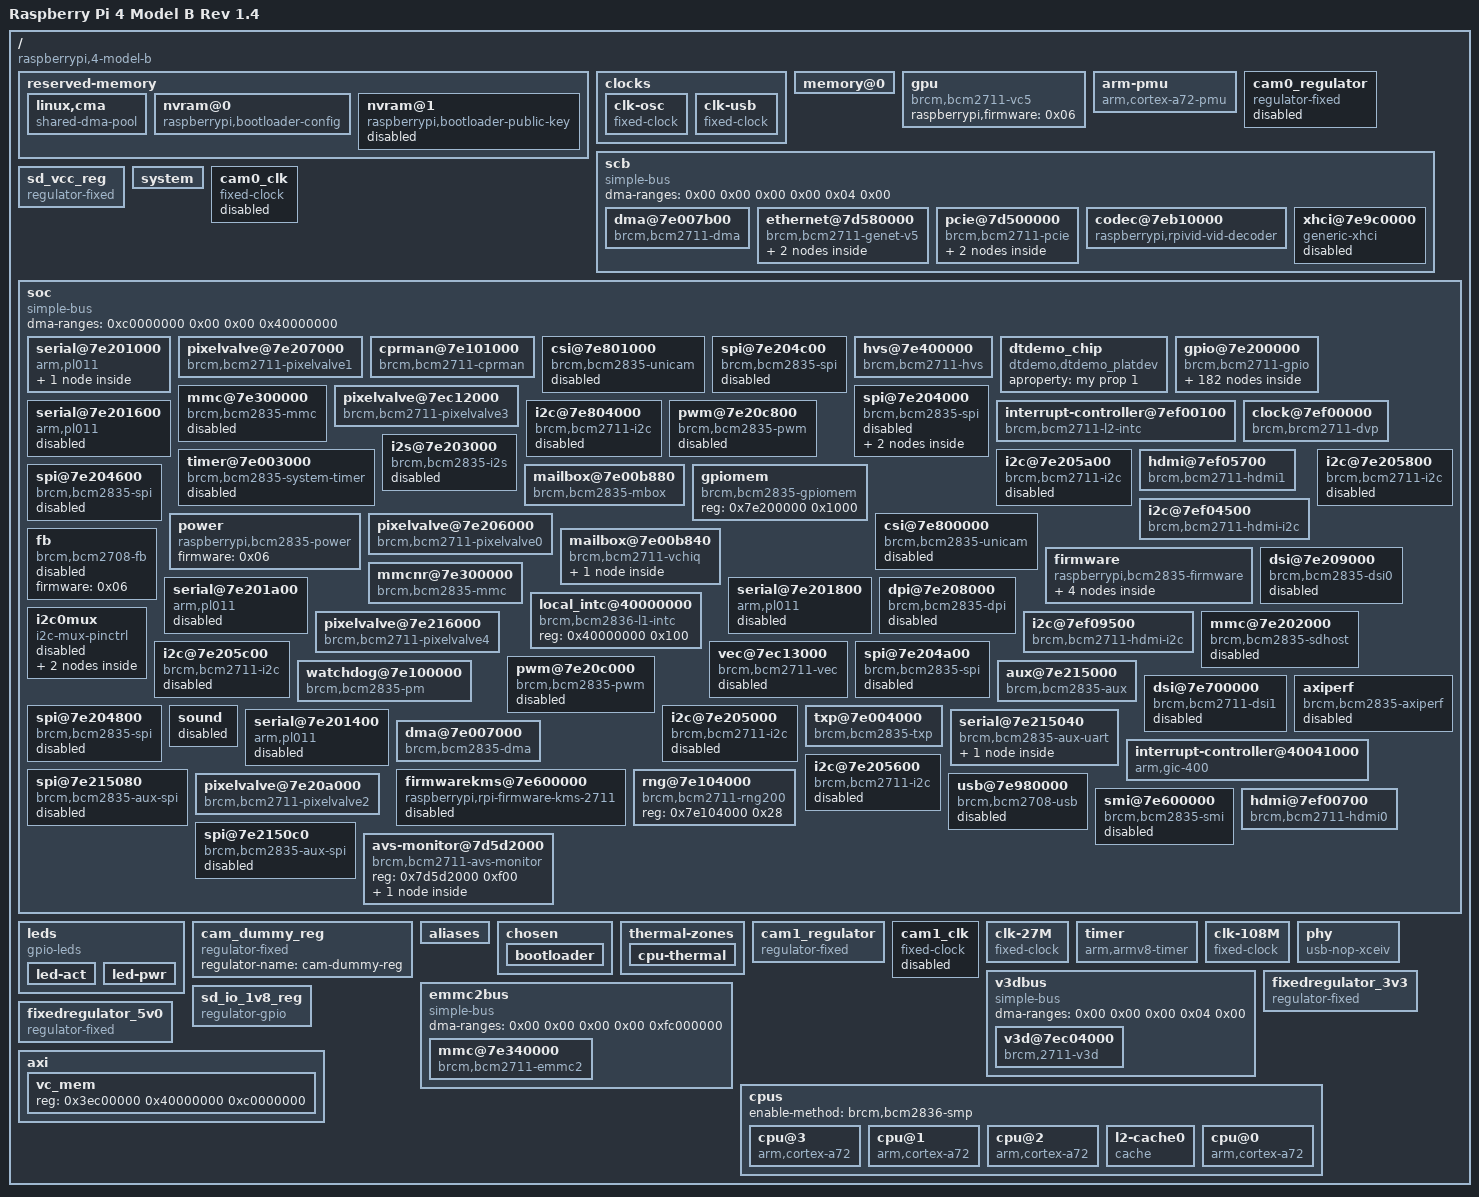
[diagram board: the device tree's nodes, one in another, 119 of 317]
/dts-v1/;

/ {
	compatible = "raspberrypi,4-model-b\0brcm,bcm2711";
	serial-number = "10000000e03e8661";
	model = "Raspberry Pi 4 Model B Rev 1.4";
	memreserve = <0x3b400000 0x4c00000>;
	interrupt-parent = <0x01>;
	#address-cells = <0x02>;
	#size-cells = <0x01>;

	reserved-memory {
		ranges;
		#address-cells = <0x02>;
		#size-cells = <0x01>;
		phandle = <0x44>;

		linux,cma {
			reusable;
			compatible = "shared-dma-pool";
			alloc-ranges = <0x00 0x00 0x30000000>;
			size = <0x14000000>;
			phandle = <0x45>;
			linux,cma-default;
		};

		nvram@0 {
			compatible = "raspberrypi,bootloader-config\0nvmem-rmem";
			status = "okay";
			#address-cells = <0x01>;
			#size-cells = <0x01>;
			no-map;
			phandle = <0x46>;
			reg = <0x00 0x3ef629c0 0x36>;
		};

		nvram@1 {
			compatible = "raspberrypi,bootloader-public-key\0nvmem-rmem";
			status = "disabled";
			#address-cells = <0x01>;
			#size-cells = <0x01>;
			no-map;
			phandle = <0x47>;
			reg = <0x00 0x00 0x00>;
		};
	};

	clocks {

		clk-osc {
			compatible = "fixed-clock";
			#clock-cells = <0x00>;
			phandle = <0x03>;
			clock-output-names = "osc";
			clock-frequency = <0x337f980>;
		};

		clk-usb {
			compatible = "fixed-clock";
			#clock-cells = <0x00>;
			phandle = <0x19>;
			clock-output-names = "otg";
			clock-frequency = <0x1c9c3800>;
		};
	};

	memory@0 {
		device_type = "memory";
		reg = <0x00 0x00 0x3b400000 0x00 0x40000000 0x40000000>;
	};

	__overrides__ {
		pwr_led_gpio = "\0\0\0Bgpios:4";
		cam0-led-ctrl;
		eth_led1 = "\0\0\0/led-modes:4";
		i2c1 = "\0\0\06status";
		i2c_vc = [00 00 00 10 73 74 61 74 75 73 00 00 00 00 35 73 74 61 74 75 73 00];
		sd_overclock = "\0\0\0:brcm,overclock-50:0";
		sdio_overclock = "\0\0\0;brcm,overclock-50:0\0\0\0\0<brcm,overclock-50:0";
		i2c0_baudrate = [00 00 00 10 63 6c 6f 63 6b 2d 66 72 65 71 75 65 6e 63 79 3a 30 00];
		sd_pio_limit = "\0\0\0:brcm,pio-limit:0";
		act_led_trigger = "\0\0\0Alinux,default-trigger";
		audio = "\0\0\07status";
		sd_debug = "\0\0\0:brcm,debug";
		cam0-pwdn-ctrl;
		cache_line_size;
		cam0-led;
		i2c1_baudrate = "\0\0\06clock-frequency:0";
		spi = "\0\0\04status";
		i2c_arm = "\0\0\06status";
		sd = "\0\0\0@status";
		pcie = "\0\0\0-status";
		pwr_led_activelow = "\0\0\0Bgpios:8";
		uart0 = "\0\0\01status";
		i2s = "\0\0\03status";
		eth_led0 = "\0\0\0/led-modes:0";
		i2c0 = [00 00 00 10 73 74 61 74 75 73 00 00 00 00 35 73 74 61 74 75 73 00];
		arm_freq;
		spi_dma4 = <0x34 0x646d6173 0x3a303d00 0x43 0x34 0x646d6173 0x3a383d00 0x43>;
		watchdog = "\0\0\08status";
		krnbt = "\0\0\00status";
		i2c_baudrate = "\0\0\06clock-frequency:0";
		i2c_vc_baudrate = [00 00 00 10 63 6c 6f 63 6b 2d 66 72 65 71 75 65 6e 63 79 3a 30 00];
		sd_poll_once = "\0\0\0@non-removable?";
		axiperf = "\0\0\0=status";
		act_led_activelow = "\0\0\0Agpios:8";
		krnbt_baudrate = "\0\0\00max-speed:0";
		sd_force_pio = "\0\0\0:brcm,force-pio?";
		pwr_led_trigger = "\0\0\0Blinux,default-trigger";
		hdmi = "\0\0\0>status\0\0\0\0?status";
		cam0-pwdn;
		uart1 = "\0\0\02status";
		i2c_arm_baudrate = "\0\0\06clock-frequency:0";
		random = "\0\0\09status";
		act_led_gpio = "\0\0\0Agpios:4";
		i2c = "\0\0\06status";
	};

	gpu {
		compatible = "brcm,bcm2711-vc5";
		status = "okay";
		phandle = <0xdb>;
		raspberrypi,firmware = <0x06>;
	};

	arm-pmu {
		compatible = "arm,cortex-a72-pmu\0arm,armv8-pmuv3\0arm,cortex-a7-pmu";
		interrupts = <0x00 0x10 0x04 0x00 0x11 0x04 0x00 0x12 0x04 0x00 0x13 0x04>;
		interrupt-affinity = <0x28 0x29 0x2a 0x2b>;
	};

	cam0_regulator {
		compatible = "regulator-fixed";
		enable-active-high;
		status = "disabled";
		phandle = <0xe5>;
		regulator-name = "cam0-reg";
	};

	scb {
		compatible = "simple-bus";
		ranges = <0x00 0x7c000000 0x00 0xfc000000 0x00 0x3800000 0x00 0x40000000 0x00 0xff800000 0x00 0x800000 0x06 0x00 0x06 0x00 0x00 0x40000000 0x00 0x00 0x00 0x00 0x00 0xfc000000>;
		#address-cells = <0x02>;
		#size-cells = <0x02>;
		phandle = <0xde>;
		dma-ranges = <0x00 0x00 0x00 0x00 0x04 0x00>;

		dma@7e007b00 {
			#dma-cells = <0x01>;
			compatible = "brcm,bcm2711-dma";
			brcm,dma-channel-mask = <0x3000>;
			interrupts = <0x00 0x59 0x04 0x00 0x5a 0x04 0x00 0x5b 0x04 0x00 0x5c 0x04>;
			phandle = <0x43>;
			reg = <0x00 0x7e007b00 0x00 0x400>;
			interrupt-names = "dma11\0dma12\0dma13\0dma14";
		};

		ethernet@7d580000 {
			phy-handle = <0x2f>;
			compatible = "brcm,bcm2711-genet-v5";
			local-mac-address = [e4 5f 01 49 32 b5];
			status = "okay";
			#address-cells = <0x01>;
			interrupts = <0x00 0x9d 0x04 0x00 0x9e 0x04>;
			#size-cells = <0x01>;
			phandle = <0xdf>;
			reg = <0x00 0x7d580000 0x00 0x10000>;
			phy-mode = "rgmii-rxid";

			mdio@e14 {
				compatible = "brcm,genet-mdio-v5";
				reg-names = "mdio";
				#address-cells = <0x01>;
				#size-cells = <0x00>;
				phandle = <0xe0>;
				reg = <0xe14 0x08>;

				ethernet-phy@1 {
					phandle = <0x2f>;
					reg = <0x01>;
					led-modes = <0x00 0x08>;
				};
			};
		};

		pcie@7d500000 {
			compatible = "brcm,bcm2711-pcie\0brcm,bcm7445-pcie";
			device_type = "pci";
			interrupt-map-mask = <0x00 0x00 0x00 0x07>;
			ranges = <0x2000000 0x00 0xc0000000 0x06 0x00 0x00 0x40000000>;
			#interrupt-cells = <0x01>;
			#address-cells = <0x03>;
			interrupts = <0x00 0x93 0x04 0x00 0x94 0x04>;
			interrupt-map = <0x00 0x00 0x00 0x01 0x01 0x00 0x8f 0x04 0x00 0x00 0x00 0x02 0x01 0x00 0x90 0x04 0x00 0x00 0x00 0x03 0x01 0x00 0x91 0x04 0x00 0x00 0x00 0x04 0x01 0x00 0x92 0x04>;
			#size-cells = <0x02>;
			phandle = <0x2d>;
			msi-parent = <0x2d>;
			reg = <0x00 0x7d500000 0x00 0x9310>;
			dma-ranges = <0x2000000 0x04 0x00 0x00 0x00 0x00 0x80000000>;
			brcm,enable-ssc;
			interrupt-names = "pcie\0msi";
			msi-controller;

			pci@0,0 {
				device_type = "pci";
				ranges;
				#address-cells = <0x03>;
				#size-cells = <0x02>;
				reg = <0x00 0x00 0x00 0x00 0x00>;

				usb@0,0 {
					resets = <0x2e 0x00>;
					reg = <0x00 0x00 0x00 0x00 0x00>;
				};
			};
		};

		codec@7eb10000 {
			compatible = "raspberrypi,rpivid-vid-decoder";
			clocks = <0x17 0x0b>;
			reg-names = "intc\0hevc";
			clock-names = "hevc";
			interrupts = <0x00 0x62 0x04>;
			reg = <0x00 0x7eb10000 0x00 0x1000 0x00 0x7eb00000 0x00 0x10000>;
		};

		xhci@7e9c0000 {
			power-domains = <0x13 0x06>;
			compatible = "generic-xhci";
			status = "disabled";
			interrupts = <0x00 0xb0 0x04>;
			phandle = <0xe1>;
			reg = <0x00 0x7e9c0000 0x00 0x100000>;
		};
	};

	sd_vcc_reg {
		compatible = "regulator-fixed";
		regulator-boot-on;
		enable-active-high;
		gpio = <0x0b 0x06 0x00>;
		phandle = <0x27>;
		regulator-min-microvolt = <0x325aa0>;
		regulator-max-microvolt = <0x325aa0>;
		regulator-name = "vcc-sd";
	};

	system {
		linux,serial = <0x10000000 0xe03e8661>;
		linux,revision = <0xb03114>;
	};

	__symbols__ {
		uart0_gpio14 = "/soc/gpio@7e200000/uart0_gpio14";
		ddc1 = "/soc/i2c@7ef09500";
		pwm = "/soc/pwm@7e20c000";
		i2c3 = "/soc/i2c@7e205600";
		gpclk1_gpio5 = "/soc/gpio@7e200000/gpclk1_gpio5";
		clk_usb = "/clocks/clk-usb";
		pixelvalve0 = "/soc/pixelvalve@7e206000";
		mii_gpio36 = "/soc/gpio@7e200000/mii_gpio36";
		minibt = "/soc/serial@7e215040/bluetooth";
		uart0_ctsrts_gpio30 = "/soc/gpio@7e200000/uart0_ctsrts_gpio30";
		spi3_pins = "/soc/gpio@7e200000/spi3_pins";
		uart4_ctsrts_gpio10 = "/soc/gpio@7e200000/uart4_ctsrts_gpio10";
		uart1_ctsrts_gpio16 = "/soc/gpio@7e200000/uart1_ctsrts_gpio16";
		uart0_gpio32 = "/soc/gpio@7e200000/uart0_gpio32";
		rgmii_irq_gpio39 = "/soc/gpio@7e200000/rgmii_irq_gpio39";
		i2c4_pins = "/soc/gpio@7e200000/i2c4";
		spi2 = "/soc/spi@7e2150c0";
		i2c0if = "/soc/i2c@7e205000";
		dsi1 = "/soc/dsi@7e700000";
		uart5_ctsrts_gpio14 = "/soc/gpio@7e200000/uart5_ctsrts_gpio14";
		clocks = "/soc/cprman@7e101000";
		i2c1 = "/soc/i2c@7e804000";
		i2c_vc = "/soc/i2c0mux/i2c@0";
		alt0 = "/soc/gpio@7e200000/alt0";
		uart4_pins = "/soc/gpio@7e200000/uart4_pins";
		rgmii_gpio35 = "/soc/gpio@7e200000/rgmii_gpio35";
		firmwarekms = "/soc/firmwarekms@7e600000";
		smi = "/soc/smi@7e600000";
		i2c5_gpio12 = "/soc/gpio@7e200000/i2c5_gpio12";
		uart1_ctsrts_gpio42 = "/soc/gpio@7e200000/uart1_ctsrts_gpio42";
		hdmi1 = "/soc/hdmi@7ef05700";
		spi0 = "/soc/spi@7e204000";
		bt = "/soc/serial@7e201000/bluetooth";
		thermal = "/soc/avs-monitor@7d5d2000/thermal";
		vdd_5v0_reg = "/fixedregulator_5v0";
		pwm1_1_gpio41 = "/soc/gpio@7e200000/pwm1_1_gpio41";
		vchiq = "/soc/mailbox@7e00b840";
		sdhost = "/soc/mmc@7e202000";
		aux = "/soc/aux@7e215000";
		cam0_regulator = "/cam0_regulator";
		gpio = "/soc/gpio@7e200000";
		gpclk0_gpio4 = "/soc/gpio@7e200000/gpclk0_gpio4";
		blconfig = "/reserved-memory/nvram@0";
		i2c3_pins = "/soc/gpio@7e200000/i2c3";
		rgmii_mdio_gpio37 = "/soc/gpio@7e200000/rgmii_mdio_gpio37";
		sdhci = "/soc/mmc@7e300000";
		blpubkey = "/reserved-memory/nvram@1";
		i2c5_gpio10 = "/soc/gpio@7e200000/i2c5_gpio10";
		gpclk2_gpio43 = "/soc/gpio@7e200000/gpclk2_gpio43";
		spi5_gpio12 = "/soc/gpio@7e200000/spi5_gpio12";
		cam1_reg = "/cam1_regulator";
		i2c3_gpio4 = "/soc/gpio@7e200000/i2c3_gpio4";
		scb = "/scb";
		xhci = "/scb/xhci@7e9c0000";
		dpi = "/soc/dpi@7e208000";
		dpi_18bit_cpadhi_gpio2 = "/soc/gpio@7e200000/dpi_18bit_cpadhi_gpio2";
		v3d = "/v3dbus/v3d@7ec04000";
		gpclk0_gpio49 = "/soc/gpio@7e200000/gpclk0_gpio49";
		audio = "/soc/mailbox@7e00b840/bcm2835_audio";
		genet = "/scb/ethernet@7d580000";
		vdd_3v3_reg = "/fixedregulator_3v3";
		uart3_pins = "/soc/gpio@7e200000/uart3_pins";
		phy1 = "/scb/ethernet@7d580000/mdio@e14/ethernet-phy@1";
		spi5_cs_pins = "/soc/gpio@7e200000/spi5_cs_pins";
		uart1_ctsrts_gpio30 = "/soc/gpio@7e200000/uart1_ctsrts_gpio30";
		gpioout = "/soc/gpio@7e200000/gpioout";
		sd_vcc_reg = "/sd_vcc_reg";
		dma = "/soc/dma@7e007000";
		spidev1 = "/soc/spi@7e204000/spidev@1";
		mmcnr = "/soc/mmcnr@7e300000";
		pwm0_0_gpio18 = "/soc/gpio@7e200000/pwm0_0_gpio18";
		gpclk2_gpio51 = "/soc/gpio@7e200000/gpclk2_gpio51";
		spi0_gpio35 = "/soc/gpio@7e200000/spi0_gpio35";
		uart4 = "/soc/serial@7e201800";
		vc4 = "/gpu";
		firmware_clocks = "/soc/firmware/clocks";
		uart5_gpio12 = "/soc/gpio@7e200000/uart5_gpio12";
		i2c3_gpio2 = "/soc/gpio@7e200000/i2c3_gpio2";
		cpu3 = "/cpus/cpu@3";
		dpi_18bit_cpadhi_gpio0 = "/soc/gpio@7e200000/dpi_18bit_cpadhi_gpio0";
		jtag_gpio48 = "/soc/gpio@7e200000/jtag_gpio48";
		cam0_clk = "/cam0_clk";
		pcm_gpio28 = "/soc/gpio@7e200000/pcm_gpio28";
		dpi_gpio0 = "/soc/gpio@7e200000/dpi_gpio0";
		power = "/soc/power";
		soc = "/soc";
		i2c6 = "/soc/i2c@7e205c00";
		pixelvalve3 = "/soc/pixelvalve@7ec12000";
		i2c0_gpio0 = "/soc/gpio@7e200000/i2c0_gpio0";
		pcm_gpio18 = "/soc/gpio@7e200000/pcm_gpio18";
		aon_intr = "/soc/interrupt-controller@7ef00100";
		i2c4_gpio8 = "/soc/gpio@7e200000/i2c4_gpio8";
		reset = "/soc/firmware/reset";
		dma40 = "/scb/dma@7e007b00";
		leds = "/leds";
		pwm1 = "/soc/pwm@7e20c800";
		system_timer = "/soc/timer@7e003000";
		uart2 = "/soc/serial@7e201400";
		uart2_pins = "/soc/gpio@7e200000/uart2_pins";
		csi1 = "/soc/csi@7e801000";
		spi2_gpio46 = "/soc/gpio@7e200000/spi2_gpio46";
		i2s_pins = "/soc/gpio@7e200000/i2s";
		cam_dummy_reg = "/cam_dummy_reg";
		firmware = "/soc/firmware";
		spi5 = "/soc/spi@7e204a00";
		cpu1 = "/cpus/cpu@1";
		spi3_gpio0 = "/soc/gpio@7e200000/spi3_gpio0";
		mmc = "/soc/mmc@7e300000";
		l2 = "/cpus/l2-cache0";
		dpi_18bit_gpio2 = "/soc/gpio@7e200000/dpi_18bit_gpio2";
		pcie0 = "/scb/pcie@7d500000";
		usbphy = "/phy";
		pwm0_0_gpio52 = "/soc/gpio@7e200000/pwm0_0_gpio52";
		i2c4 = "/soc/i2c@7e205800";
		pixelvalve1 = "/soc/pixelvalve@7e207000";
		i2c6_gpio0 = "/soc/gpio@7e200000/i2c6_gpio0";
		i2c1_gpio46 = "/soc/gpio@7e200000/i2c1_gpio46";
		spi = "/soc/spi@7e204000";
		spi0_pins = "/soc/gpio@7e200000/spi0_pins";
		i2c_arm = "/soc/i2c@7e804000";
		i2c4_gpio6 = "/soc/gpio@7e200000/i2c4_gpio6";
		clk_osc = "/clocks/clk-osc";
		uart0 = "/soc/serial@7e201000";
		i2c1_pins = "/soc/gpio@7e200000/i2c1";
		rmem = "/reserved-memory";
		cpu_thermal = "/thermal-zones/cpu-thermal";
		spi3 = "/soc/spi@7e204600";
		fb = "/soc/fb";
		txp = "/soc/txp@7e004000";
		dpi_18bit_gpio0 = "/soc/gpio@7e200000/dpi_18bit_gpio0";
		spi0_gpio7 = "/soc/gpio@7e200000/spi0_gpio7";
		ddc0 = "/soc/i2c@7ef04500";
		uart1_pins = "/soc/gpio@7e200000/uart1_pins";
		spi6_cs_pins = "/soc/gpio@7e200000/spi6_cs_pins";
		pwm0_0_gpio12 = "/soc/gpio@7e200000/pwm0_0_gpio12";
		i2c1_gpio44 = "/soc/gpio@7e200000/i2c1_gpio44";
		cma = "/reserved-memory/linux,cma";
		pwm0_1_gpio19 = "/soc/gpio@7e200000/pwm0_1_gpio19";
		spi6_pins = "/soc/gpio@7e200000/spi6_pins";
		i2c0_gpio28 = "/soc/gpio@7e200000/i2c0_gpio28";
		spi4_gpio4 = "/soc/gpio@7e200000/spi4_gpio4";
		avs_monitor = "/soc/avs-monitor@7d5d2000";
		cam1_clk = "/cam1_clk";
		i2s = "/soc/i2s@7e203000";
		emmc_gpio48 = "/soc/gpio@7e200000/emmc_gpio48";
		spi1 = "/soc/spi@7e215080";
		usb = "/soc/usb@7e980000";
		dsi0 = "/soc/dsi@7e209000";
		i2c0_gpio46 = "/soc/gpio@7e200000/i2c0_gpio46";
		i2c1_gpio2 = "/soc/gpio@7e200000/i2c1_gpio2";
		uart2_gpio0 = "/soc/gpio@7e200000/uart2_gpio0";
		dvp = "/soc/clock@7ef00000";
		expgpio = "/soc/firmware/gpio";
		uart0_ctsrts_gpio38 = "/soc/gpio@7e200000/uart0_ctsrts_gpio38";
		pm = "/soc/watchdog@7e100000";
		audio_pins = "/soc/gpio@7e200000/audio_pins";
		i2c0 = "/soc/i2c0mux/i2c@0";
		pcm_gpio50 = "/soc/gpio@7e200000/pcm_gpio50";
		spi1_gpio16 = "/soc/gpio@7e200000/spi1_gpio16";
		i2c0mux = "/soc/i2c0mux";
		i2c_csi_dsi = "/soc/i2c0mux/i2c@1";
		i2c0_pins = "/soc/gpio@7e200000/i2c0";
		spi3_cs_pins = "/soc/gpio@7e200000/spi3_cs_pins";
		pwr_led = "/leds/led-pwr";
		watchdog = "/soc/watchdog@7e100000";
		jtag_gpio22 = "/soc/gpio@7e200000/jtag_gpio22";
		pwm0_1_gpio45 = "/soc/gpio@7e200000/pwm0_1_gpio45";
		clk_27MHz = "/clk-27M";
		rgmii_mdio_gpio28 = "/soc/gpio@7e200000/rgmii_mdio_gpio28";
		hdmi0 = "/soc/hdmi@7ef00700";
		spi2_gpio40 = "/soc/gpio@7e200000/spi2_gpio40";
		uart0_pins = "/soc/gpio@7e200000/uart0_pins";
		vec = "/soc/vec@7ec13000";
		local_intc = "/soc/local_intc@40000000";
		i2c0_gpio44 = "/soc/gpio@7e200000/i2c0_gpio44";
		spi0_gpio46 = "/soc/gpio@7e200000/spi0_gpio46";
		spi5_pins = "/soc/gpio@7e200000/spi5_pins";
		axiperf = "/soc/axiperf";
		gicv2 = "/soc/interrupt-controller@40041000";
		pwm0_1_gpio53 = "/soc/gpio@7e200000/pwm0_1_gpio53";
		spi0_cs_pins = "/soc/gpio@7e200000/spi0_cs_pins";
		i2c6_pins = "/soc/gpio@7e200000/i2c6";
		sound = "/soc/sound";
		uart5 = "/soc/serial@7e201a00";
		hvs = "/soc/hvs@7e400000";
		uart2_ctsrts_gpio2 = "/soc/gpio@7e200000/uart2_ctsrts_gpio2";
		spi6_gpio18 = "/soc/gpio@7e200000/spi6_gpio18";
		uart3_gpio4 = "/soc/gpio@7e200000/uart3_gpio4";
		rgmii_irq_gpio34 = "/soc/gpio@7e200000/rgmii_irq_gpio34";
		uart3_ctsrts_gpio6 = "/soc/gpio@7e200000/uart3_ctsrts_gpio6";
		uart0_ctsrts_gpio16 = "/soc/gpio@7e200000/uart0_ctsrts_gpio16";
		v3dbus = "/v3dbus";
		act_led = "/leds/led-act";
		gpclk2_gpio6 = "/soc/gpio@7e200000/gpclk2_gpio6";
		spidev0 = "/soc/spi@7e204000/spidev@0";
		pixelvalve4 = "/soc/pixelvalve@7e216000";
		sdhost_gpio48 = "/soc/gpio@7e200000/sdhost_gpio48";
		genet_mdio = "/scb/ethernet@7d580000/mdio@e14";
		bt_pins = "/soc/gpio@7e200000/bt_pins";
		dpi_16bit_gpio2 = "/soc/gpio@7e200000/dpi_16bit_gpio2";
		emmc_gpio34 = "/soc/gpio@7e200000/emmc_gpio34";
		gpclk1_gpio44 = "/soc/gpio@7e200000/gpclk1_gpio44";
		uart1_gpio14 = "/soc/gpio@7e200000/uart1_gpio14";
		uart0_gpio36 = "/soc/gpio@7e200000/uart0_gpio36";
		emmc2bus = "/emmc2bus";
		uart3 = "/soc/serial@7e201600";
		sdio_pins = "/soc/gpio@7e200000/sdio_pins";
		dpi_16bit_cpadhi_gpio2 = "/soc/gpio@7e200000/dpi_16bit_cpadhi_gpio2";
		pwm0_1_gpio13 = "/soc/gpio@7e200000/pwm0_1_gpio13";
		spi6 = "/soc/spi@7e204c00";
		cpus = "/cpus";
		sd_io_1v8_reg = "/sd_io_1v8_reg";
		spi4_pins = "/soc/gpio@7e200000/spi4_pins";
		cpu2 = "/cpus/cpu@2";
		clk_108MHz = "/clk-108M";
		uart1_gpio32 = "/soc/gpio@7e200000/uart1_gpio32";
		pwm1_0_gpio40 = "/soc/gpio@7e200000/pwm1_0_gpio40";
		i2c5_pins = "/soc/gpio@7e200000/i2c5";
		i2c5 = "/soc/i2c@7e205a00";
		pixelvalve2 = "/soc/pixelvalve@7e20a000";
		emmc2 = "/emmc2bus/mmc@7e340000";
		dpi_16bit_gpio0 = "/soc/gpio@7e200000/dpi_16bit_gpio0";
		gpclk1_gpio42 = "/soc/gpio@7e200000/gpclk1_gpio42";
		mailbox = "/soc/mailbox@7e00b880";
		i2c6_gpio22 = "/soc/gpio@7e200000/i2c6_gpio22";
		uart4_gpio8 = "/soc/gpio@7e200000/uart4_gpio8";
		uart1_gpio40 = "/soc/gpio@7e200000/uart1_gpio40";
		emmc_gpio22 = "/soc/gpio@7e200000/emmc_gpio22";
		mii_gpio28 = "/soc/gpio@7e200000/mii_gpio28";
		uart1 = "/soc/serial@7e215040";
		dpi_16bit_cpadhi_gpio0 = "/soc/gpio@7e200000/dpi_16bit_cpadhi_gpio0";
		uart5_pins = "/soc/gpio@7e200000/uart5_pins";
		spi4_cs_pins = "/soc/gpio@7e200000/spi4_cs_pins";
		csi0 = "/soc/csi@7e800000";
		spi4 = "/soc/spi@7e204800";
		cam0_reg = "/cam_dummy_reg";
		random = "/soc/rng@7e104000";
		i2c = "/soc/i2c@7e804000";
		cpu0 = "/cpus/cpu@0";
		vcio = "/soc/firmware/vcio";
		i2c_slave_gpio8 = "/soc/gpio@7e200000/i2c_slave_gpio8";
		gpclk1_gpio50 = "/soc/gpio@7e200000/gpclk1_gpio50";
	};

	cam0_clk {
		compatible = "fixed-clock";
		status = "disabled";
		#clock-cells = <0x00>;
		phandle = <0xe6>;
	};

	soc {
		compatible = "simple-bus";
		ranges = <0x7e000000 0x00 0xfe000000 0x1800000 0x7c000000 0x00 0xfc000000 0x2000000 0x40000000 0x00 0xff800000 0x800000>;
		#address-cells = <0x01>;
		#size-cells = <0x01>;
		phandle = <0x49>;
		dma-ranges = <0xc0000000 0x00 0x00 0x40000000>;

		serial@7e201000 {
			compatible = "arm,pl011\0arm,primecell";
			clocks = <0x08 0x13 0x08 0x14>;
			uart-has-rtscts;
			clock-names = "uartclk\0apb_pclk";
			status = "okay";
			interrupts = <0x00 0x79 0x04>;
			skip-init;
			phandle = <0x31>;
			arm,primecell-periphid = <0x241011>;
			reg = <0x7e201000 0x200>;
			pinctrl-0 = <0x09 0x0a>;
			cts-event-workaround;
			pinctrl-names = "default";

			bluetooth {
				compatible = "brcm,bcm43438-bt";
				shutdown-gpios = <0x0b 0x00 0x00>;
				max-speed = <0x2dc6c0>;
				status = "disabled";
				phandle = <0x30>;
			};
		};

		pixelvalve@7e207000 {
			compatible = "brcm,bcm2711-pixelvalve1";
			status = "okay";
			interrupts = <0x00 0x6e 0x04>;
			phandle = <0xcd>;
			reg = <0x7e207000 0x100>;
		};

		cprman@7e101000 {
			compatible = "brcm,bcm2711-cprman";
			clocks = <0x03 0x04 0x00 0x04 0x01 0x04 0x02 0x05 0x00 0x05 0x01 0x05 0x02>;
			firmware = <0x06>;
			#clock-cells = <0x01>;
			phandle = <0x08>;
			reg = <0x7e101000 0x2000>;
		};

		csi@7e801000 {
			power-domains = <0x13 0x0d>;
			compatible = "brcm,bcm2835-unicam";
			clocks = <0x08 0x2e 0x17 0x04>;
			clock-names = "lp\0vpu";
			status = "disabled";
			#address-cells = <0x01>;
			interrupts = <0x00 0x67 0x04>;
			brcm,num-data-lanes = <0x02>;
			#size-cells = <0x00>;
			#clock-cells = <0x01>;
			phandle = <0xd8>;
			reg = <0x7e801000 0x800 0x7e802004 0x04>;
		};

		spi@7e204c00 {
			compatible = "brcm,bcm2835-spi";
			clocks = <0x08 0x14>;
			status = "disabled";
			#address-cells = <0x01>;
			interrupts = <0x00 0x76 0x04>;
			#size-cells = <0x00>;
			phandle = <0xc7>;
			reg = <0x7e204c00 0x200>;
		};

		hvs@7e400000 {
			compatible = "brcm,bcm2711-hvs";
			clocks = <0x17 0x04>;
			status = "okay";
			interrupts = <0x00 0x61 0x04>;
			phandle = <0xbc>;
			reg = <0x7e400000 0x8000>;
		};


		/* our demo pseudo h/w chip
                From DTSpec: https://github.com/devicetree-org/devicetree-specification/releases/download/v0.3-rc2/devicetree-specification-v0.3-rc2.pdf
                 "This list of strings should be used by a client program for device driver selection. The property
		  value consists of a concatenated list of null terminated strings, from most specific to most general. They
		  allow a device to express its compatibility with a family of similar devices, potentially allowing a single
		  device driver to match against several devices. "
                */
                dtdemo_chip {
                        compatible = "dtdemo,dtdemo_platdev";
                        aproperty = "my prop 1";
			status = "okay";
                };


		gpio@7e200000 {
			compatible = "brcm,bcm2711-gpio";
			gpio-line-names = "ID_SDA\0ID_SCL\0SDA1\0SCL1\0GPIO_GCLK\0GPIO5\0GPIO6\0SPI_CE1_N\0SPI_CE0_N\0SPI_MISO\0SPI_MOSI\0SPI_SCLK\0GPIO12\0GPIO13\0TXD1\0RXD1\0GPIO16\0GPIO17\0GPIO18\0GPIO19\0GPIO20\0GPIO21\0GPIO22\0GPIO23\0GPIO24\0GPIO25\0GPIO26\0GPIO27\0RGMII_MDIO\0RGMIO_MDC\0CTS0\0RTS0\0TXD0\0RXD0\0SD1_CLK\0SD1_CMD\0SD1_DATA0\0SD1_DATA1\0SD1_DATA2\0SD1_DATA3\0PWM0_MISO\0PWM1_MOSI\0STATUS_LED_G_CLK\0SPIFLASH_CE_N\0SDA0\0SCL0\0RGMII_RXCLK\0RGMII_RXCTL\0RGMII_RXD0\0RGMII_RXD1\0RGMII_RXD2\0RGMII_RXD3\0RGMII_TXCLK\0RGMII_TXCTL\0RGMII_TXD0\0RGMII_TXD1\0RGMII_TXD2\0RGMII_TXD3";
			gpio-controller;
			gpio-ranges = <0x07 0x00 0x00 0x3a>;
			#interrupt-cells = <0x02>;
			interrupts = <0x00 0x71 0x04 0x00 0x72 0x04>;
			phandle = <0x07>;
			reg = <0x7e200000 0xb4>;
			#gpio-cells = <0x02>;
			pinctrl-names = "default";
			interrupt-controller;

			uart0_gpio14 {
				brcm,pins = <0x0e 0x0f>;
				phandle = <0x60>;
				brcm,function = <0x04>;
			};

			i2c3 {
				brcm,pins = <0x04 0x05>;
				phandle = <0xab>;
				brcm,pull = <0x02>;
				brcm,function = <0x02>;
			};

			gpclk1_gpio5 {
				brcm,pins = <0x05>;
				phandle = <0x50>;
				brcm,function = <0x04>;
			};

			mii_gpio36 {
				phandle = <0x7c>;

				pins-mii {
					pins = "gpio36\0gpio37\0gpio38\0gpio39";
					function = "alt5";
				};
			};

			uart0_ctsrts_gpio30 {
				brcm,pins = <0x1e 0x1f>;
				phandle = <0x62>;
				brcm,pull = <0x02 0x00>;
				brcm,function = <0x07>;
			};

			spi3_pins {
				brcm,pins = <0x01 0x02 0x03>;
				phandle = <0xa2>;
				brcm,function = <0x07>;
			};

			uart4_ctsrts_gpio10 {
				phandle = <0x95>;

				pin-cts {
					pins = "gpio10";
					function = "alt4";
					bias-pull-up;
				};

				pin-rts {
					pins = "gpio11";
					bias-disable;
					function = "alt4";
				};
			};

			uart1_ctsrts_gpio16 {
				brcm,pins = <0x10 0x11>;
				phandle = <0x67>;
				brcm,function = <0x02>;
			};

			uart0_gpio32 {
				brcm,pins = <0x20 0x21>;
				phandle = <0x63>;
				brcm,pull = <0x00 0x02>;
				brcm,function = <0x07>;
			};

			rgmii_irq_gpio39 {
				phandle = <0x87>;

				pin-irq {
					pins = "gpio39";
					function = "alt4";
				};
			};

			uart5_ctsrts_gpio14 {
				phandle = <0x97>;

				pin-cts {
					pins = "gpio14";
					function = "alt4";
					bias-pull-up;
				};

				pin-rts {
					pins = "gpio15";
					bias-disable;
					function = "alt4";
				};
			};

			i2c1 {
				brcm,pins = <0x02 0x03>;
				phandle = <0x18>;
				brcm,pull = <0x02>;
				brcm,function = <0x04>;
			};

			alt0 {
				brcm,pins = <0x04 0x05 0x07 0x08 0x09 0x0a 0x0b>;
				phandle = <0x99>;
				brcm,function = <0x04>;
			};

			uart4_pins {
				brcm,pins = <0x08 0x09>;
				phandle = <0xb1>;
				brcm,pull = <0x00 0x02>;
				brcm,function = <0x03>;
			};

			rgmii_gpio35 {
				phandle = <0x85>;

				pin-start-stop {
					pins = "gpio35";
					function = "alt4";
				};

				pin-rx-ok {
					pins = "gpio36";
					function = "alt4";
				};
			};

			i2c5_gpio12 {
				phandle = <0x76>;

				pin-scl {
					pins = "gpio13";
					bias-disable;
					function = "alt5";
				};

				pin-sda {
					pins = "gpio12";
					function = "alt5";
					bias-pull-up;
				};
			};

			uart1_ctsrts_gpio42 {
				brcm,pins = <0x2a 0x2b>;
				phandle = <0x6b>;
				brcm,function = <0x02>;
			};

			pwm1_1_gpio41 {
				phandle = <0x1c>;

				pin-pwm {
					pins = "gpio41";
					bias-disable;
					function = "alt0";
				};
			};

			gpclk0_gpio4 {
				brcm,pins = <0x04>;
				phandle = <0x4f>;
				brcm,function = <0x04>;
			};

			rgmii_mdio_gpio37 {
				phandle = <0x89>;

				pins-mdio {
					pins = "gpio37\0gpio38";
					function = "alt4";
				};
			};

			i2c5_gpio10 {
				phandle = <0x75>;

				pin-scl {
					pins = "gpio11";
					bias-disable;
					function = "alt5";
				};

				pin-sda {
					pins = "gpio10";
					function = "alt5";
					bias-pull-up;
				};
			};

			gpclk2_gpio43 {
				brcm,pins = <0x2b>;
				phandle = <0x54>;
				brcm,pull = <0x00>;
				brcm,function = <0x04>;
			};

			spi5_gpio12 {
				phandle = <0x8e>;

				pins-spi {
					pins = "gpio12\0gpio13\0gpio14\0gpio15";
					function = "alt3";
				};
			};

			i2c3_gpio4 {
				phandle = <0x72>;

				pin-scl {
					pins = "gpio5";
					bias-disable;
					function = "alt5";
				};

				pin-sda {
					pins = "gpio4";
					function = "alt5";
					bias-pull-up;
				};
			};

			dpi_18bit_cpadhi_gpio2 {
				brcm,pins = <0x02 0x03 0x04 0x05 0x06 0x07 0x08 0x09 0x0c 0x0d 0x0e 0x0f 0x10 0x11 0x14 0x15 0x16 0x17 0x18 0x19>;
				phandle = <0x9b>;
				brcm,function = <0x06>;
			};

			gpclk0_gpio49 {
				phandle = <0x6c>;

				pin-gpclk {
					pins = "gpio49";
					bias-disable;
					function = "alt1";
				};
			};

			uart3_pins {
				brcm,pins = <0x04 0x05>;
				phandle = <0xb0>;
				brcm,pull = <0x00 0x02>;
				brcm,function = <0x03>;
			};

			spi5_cs_pins {
				brcm,pins = <0x0c 0x1a>;
				phandle = <0xa7>;
				brcm,function = <0x01>;
			};

			uart1_ctsrts_gpio30 {
				brcm,pins = <0x1e 0x1f>;
				phandle = <0x69>;
				brcm,function = <0x02>;
			};

			gpioout {
				brcm,pins = <0x06>;
				phandle = <0x98>;
				brcm,function = <0x01>;
			};

			pwm0_0_gpio18 {
				phandle = <0x7f>;

				pin-pwm {
					pins = "gpio18";
					bias-disable;
					function = "alt5";
				};
			};

			gpclk2_gpio51 {
				phandle = <0x6e>;

				pin-gpclk {
					pins = "gpio51";
					bias-disable;
					function = "alt1";
				};
			};

			spi0_gpio35 {
				brcm,pins = <0x23 0x24 0x25 0x26 0x27>;
				phandle = <0x5d>;
				brcm,function = <0x04>;
			};

			uart5_gpio12 {
				phandle = <0x96>;

				pin-tx {
					pins = "gpio12";
					bias-disable;
					function = "alt4";
				};

				pin-rx {
					pins = "gpio13";
					function = "alt4";
					bias-pull-up;
				};
			};

			i2c3_gpio2 {
				phandle = <0x71>;

				pin-scl {
					pins = "gpio3";
					bias-disable;
					function = "alt5";
				};

				pin-sda {
					pins = "gpio2";
					function = "alt5";
					bias-pull-up;
				};
			};

			dpi_18bit_cpadhi_gpio0 {
				brcm,pins = <0x00 0x01 0x02 0x03 0x04 0x05 0x06 0x07 0x08 0x09 0x0c 0x0d 0x0e 0x0f 0x10 0x11 0x14 0x15 0x16 0x17 0x18 0x19>;
				phandle = <0x9a>;
				brcm,pull = <0x00>;
				brcm,function = <0x06>;
			};

			jtag_gpio48 {
				phandle = <0x7a>;

				pins-jtag {
					pins = "gpio48\0gpio49\0gpio50\0gpio51\0gpio52\0gpio53";
					function = "alt4";
				};
			};

			pcm_gpio28 {
				brcm,pins = <0x1c 0x1d 0x1e 0x1f>;
				phandle = <0x5a>;
				brcm,function = <0x06>;
			};

			dpi_gpio0 {
				brcm,pins = <0x00 0x01 0x02 0x03 0x04 0x05 0x06 0x07 0x08 0x09 0x0a 0x0b 0x0c 0x0d 0x0e 0x0f 0x10 0x11 0x12 0x13 0x14 0x15 0x16 0x17 0x18 0x19 0x1a 0x1b>;
				phandle = <0x4c>;
				brcm,function = <0x06>;
			};

			i2c6 {
				brcm,pins = <0x16 0x17>;
				phandle = <0xae>;
				brcm,pull = <0x02>;
				brcm,function = <0x02>;
			};

			i2c0_gpio0 {
				brcm,pins = <0x00 0x01>;
				phandle = <0x11>;
				brcm,function = <0x04>;
			};

			pcm_gpio18 {
				brcm,pins = <0x12 0x13 0x14 0x15>;
				phandle = <0x59>;
				brcm,function = <0x04>;
			};

			i2c4_gpio8 {
				phandle = <0x74>;

				pin-scl {
					pins = "gpio9";
					bias-disable;
					function = "alt5";
				};

				pin-sda {
					pins = "gpio8";
					function = "alt5";
					bias-pull-up;
				};
			};

			uart2_pins {
				brcm,pins = <0x00 0x01>;
				phandle = <0xaf>;
				brcm,pull = <0x00 0x02>;
				brcm,function = <0x03>;
			};

			spi2_gpio46 {
				phandle = <0x8b>;

				pins-spi {
					pins = "gpio46\0gpio47\0gpio48\0gpio49\0gpio50";
					function = "alt5";
				};
			};

			spi3_gpio0 {
				phandle = <0x8c>;

				pins-spi {
					pins = "gpio0\0gpio1\0gpio2\0gpio3";
					function = "alt3";
				};
			};

			dpi_18bit_gpio2 {
				brcm,pins = <0x02 0x03 0x04 0x05 0x06 0x07 0x08 0x09 0x0a 0x0b 0x0c 0x0d 0x0e 0x0f 0x10 0x11 0x12 0x13 0x14 0x15>;
				phandle = <0x9d>;
				brcm,function = <0x06>;
			};

			pwm0_0_gpio52 {
				phandle = <0x83>;

				pin-pwm {
					pins = "gpio52";
					bias-disable;
					function = "alt1";
				};
			};

			i2c4 {
				brcm,pins = <0x08 0x09>;
				phandle = <0xac>;
				brcm,pull = <0x02>;
				brcm,function = <0x02>;
			};

			i2c6_gpio0 {
				phandle = <0x77>;

				pin-scl {
					pins = "gpio1";
					bias-disable;
					function = "alt5";
				};

				pin-sda {
					pins = "gpio0";
					function = "alt5";
					bias-pull-up;
				};
			};

			i2c1_gpio46 {
				phandle = <0x70>;

				pin-scl {
					pins = "gpio47";
					bias-disable;
					function = "alt1";
				};

				pin-sda {
					pins = "gpio46";
					function = "alt1";
					bias-pull-up;
				};
			};

			spi0_pins {
				brcm,pins = <0x09 0x0a 0x0b>;
				phandle = <0x0e>;
				brcm,function = <0x04>;
			};

			i2c4_gpio6 {
				phandle = <0x73>;

				pin-scl {
					pins = "gpio7";
					bias-disable;
					function = "alt5";
				};

				pin-sda {
					pins = "gpio6";
					function = "alt5";
					bias-pull-up;
				};
			};

			dpi_18bit_gpio0 {
				brcm,pins = <0x00 0x01 0x02 0x03 0x04 0x05 0x06 0x07 0x08 0x09 0x0a 0x0b 0x0c 0x0d 0x0e 0x0f 0x10 0x11 0x12 0x13 0x14 0x15>;
				phandle = <0x9c>;
				brcm,function = <0x06>;
			};

			spi0_gpio7 {
				brcm,pins = <0x07 0x08 0x09 0x0a 0x0b>;
				phandle = <0x5c>;
				brcm,function = <0x04>;
			};

			uart1_pins {
				brcm,pins;
				phandle = <0x15>;
				brcm,pull;
				brcm,function;
			};

			spi6_cs_pins {
				brcm,pins = <0x12 0x1b>;
				phandle = <0xa9>;
				brcm,function = <0x01>;
			};

			pwm0_0_gpio12 {
				phandle = <0x7e>;

				pin-pwm {
					pins = "gpio12";
					bias-disable;
					function = "alt0";
				};
			};

			i2c1_gpio44 {
				brcm,pins = <0x2c 0x2d>;
				phandle = <0x57>;
				brcm,function = <0x06>;
			};

			pwm0_1_gpio19 {
				phandle = <0x81>;

				pin-pwm {
					pins = "gpio19";
					bias-disable;
					function = "alt5";
				};
			};

			spi6_pins {
				brcm,pins = <0x13 0x14 0x15>;
				phandle = <0xa8>;
				brcm,function = <0x07>;
			};

			i2c0_gpio28 {
				brcm,pins = <0x1c 0x1d>;
				phandle = <0x55>;
				brcm,function = <0x04>;
			};

			spi4_gpio4 {
				phandle = <0x8d>;

				pins-spi {
					pins = "gpio4\0gpio5\0gpio6\0gpio7";
					function = "alt3";
				};
			};

			i2s {
				brcm,pins = <0x12 0x13 0x14 0x15>;
				phandle = <0x0d>;
				brcm,function = <0x04>;
			};

			emmc_gpio48 {
				brcm,pins = <0x30 0x31 0x32 0x33 0x34 0x35>;
				phandle = <0x16>;
				brcm,function = <0x07>;
			};

			i2c0_gpio46 {
				phandle = <0x6f>;

				pin-scl {
					pins = "gpio47";
					bias-disable;
					function = "alt0";
				};

				pin-sda {
					pins = "gpio46";
					function = "alt0";
					bias-pull-up;
				};
			};

			i2c1_gpio2 {
				brcm,pins = <0x02 0x03>;
				phandle = <0x56>;
				brcm,function = <0x04>;
			};

			uart2_gpio0 {
				phandle = <0x90>;

				pin-tx {
					pins = "gpio0";
					bias-disable;
					function = "alt4";
				};

				pin-rx {
					pins = "gpio1";
					function = "alt4";
					bias-pull-up;
				};
			};

			uart0_ctsrts_gpio38 {
				brcm,pins = <0x26 0x27>;
				phandle = <0x65>;
				brcm,function = <0x06>;
			};

			audio_pins {
				brcm,pins = <0x28 0x29>;
				phandle = <0x24>;
				brcm,function = <0x04>;
			};

			i2c0 {
				brcm,pins = <0x00 0x01>;
				phandle = <0xaa>;
				brcm,pull = <0x02>;
				brcm,function = <0x04>;
			};

			pcm_gpio50 {
				phandle = <0x7d>;

				pins-pcm {
					pins = "gpio50\0gpio51\0gpio52\0gpio53";
					function = "alt2";
				};
			};

			spi1_gpio16 {
				brcm,pins = <0x10 0x11 0x12 0x13 0x14 0x15>;
				phandle = <0x5e>;
				brcm,function = <0x03>;
			};

			spi3_cs_pins {
				brcm,pins = <0x00 0x18>;
				phandle = <0xa3>;
				brcm,function = <0x01>;
			};

			jtag_gpio22 {
				brcm,pins = <0x16 0x17 0x18 0x19 0x1a 0x1b>;
				phandle = <0x58>;
				brcm,function = <0x03>;
			};

			pwm0_1_gpio45 {
				phandle = <0x82>;

				pin-pwm {
					pins = "gpio45";
					bias-disable;
					function = "alt0";
				};
			};

			rgmii_mdio_gpio28 {
				phandle = <0x88>;

				pins-mdio {
					pins = "gpio28\0gpio29";
					function = "alt5";
				};
			};

			spi2_gpio40 {
				brcm,pins = <0x28 0x29 0x2a 0x2b 0x2c 0x2d>;
				phandle = <0x5f>;
				brcm,function = <0x03>;
			};

			uart0_pins {
				brcm,pins = <0x1e 0x1f 0x20 0x21>;
				phandle = <0x09>;
				brcm,pull = <0x02 0x00 0x00 0x02>;
				brcm,function = <0x07>;
			};

			i2c0_gpio44 {
				brcm,pins = <0x2c 0x2d>;
				phandle = <0x12>;
				brcm,function = <0x05>;
			};

			spi0_gpio46 {
				phandle = <0x8a>;

				pins-spi {
					pins = "gpio46\0gpio47\0gpio48\0gpio49";
					function = "alt2";
				};
			};

			spi5_pins {
				brcm,pins = <0x0d 0x0e 0x0f>;
				phandle = <0xa6>;
				brcm,function = <0x07>;
			};

			pwm0_1_gpio53 {
				phandle = <0x84>;

				pin-pwm {
					pins = "gpio53";
					bias-disable;
					function = "alt1";
				};
			};

			spi0_cs_pins {
				brcm,pins = <0x08 0x07>;
				phandle = <0x0f>;
				brcm,function = <0x01>;
			};

			uart2_ctsrts_gpio2 {
				phandle = <0x91>;

				pin-cts {
					pins = "gpio2";
					function = "alt4";
					bias-pull-up;
				};

				pin-rts {
					pins = "gpio3";
					bias-disable;
					function = "alt4";
				};
			};

			spi6_gpio18 {
				phandle = <0x8f>;

				pins-spi {
					pins = "gpio18\0gpio19\0gpio20\0gpio21";
					function = "alt3";
				};
			};

			uart3_gpio4 {
				phandle = <0x92>;

				pin-tx {
					pins = "gpio4";
					bias-disable;
					function = "alt4";
				};

				pin-rx {
					pins = "gpio5";
					function = "alt4";
					bias-pull-up;
				};
			};

			rgmii_irq_gpio34 {
				phandle = <0x86>;

				pin-irq {
					pins = "gpio34";
					function = "alt5";
				};
			};

			uart3_ctsrts_gpio6 {
				phandle = <0x93>;

				pin-cts {
					pins = "gpio6";
					function = "alt4";
					bias-pull-up;
				};

				pin-rts {
					pins = "gpio7";
					bias-disable;
					function = "alt4";
				};
			};

			uart0_ctsrts_gpio16 {
				brcm,pins = <0x10 0x11>;
				phandle = <0x61>;
				brcm,function = <0x07>;
			};

			gpclk2_gpio6 {
				brcm,pins = <0x06>;
				phandle = <0x53>;
				brcm,function = <0x04>;
			};

			sdhost_gpio48 {
				brcm,pins = <0x30 0x31 0x32 0x33 0x34 0x35>;
				phandle = <0x5b>;
				brcm,function = <0x04>;
			};

			bt_pins {
				brcm,pins = [2d 00];
				phandle = <0x0a>;
				brcm,pull = <0x02>;
				brcm,function = <0x00>;
			};

			dpi_16bit_gpio2 {
				brcm,pins = <0x02 0x03 0x04 0x05 0x06 0x07 0x08 0x09 0x0a 0x0b 0x0c 0x0d 0x0e 0x0f 0x10 0x11 0x12 0x13>;
				phandle = <0x9f>;
				brcm,function = <0x06>;
			};

			emmc_gpio34 {
				brcm,pins = <0x22 0x23 0x24 0x25 0x26 0x27>;
				phandle = <0x4e>;
				brcm,pull = <0x00 0x02 0x02 0x02 0x02 0x02>;
				brcm,function = <0x07>;
			};

			gpclk1_gpio44 {
				brcm,pins = <0x2c>;
				phandle = <0x52>;
				brcm,function = <0x04>;
			};

			uart1_gpio14 {
				brcm,pins = <0x0e 0x0f>;
				phandle = <0x66>;
				brcm,function = <0x02>;
			};

			uart0_gpio36 {
				brcm,pins = <0x24 0x25>;
				phandle = <0x64>;
				brcm,function = <0x06>;
			};

			sdio_pins {
				brcm,pins = <0x22 0x23 0x24 0x25 0x26 0x27>;
				phandle = <0x25>;
				brcm,pull = <0x00 0x02 0x02 0x02 0x02 0x02>;
				brcm,function = <0x07>;
			};

			dpi_16bit_cpadhi_gpio2 {
				brcm,pins = <0x02 0x03 0x04 0x05 0x06 0x07 0x08 0x0c 0x0d 0x0e 0x0f 0x10 0x11 0x14 0x15 0x16 0x17 0x18>;
				phandle = <0xa1>;
				brcm,function = <0x06>;
			};

			pwm0_1_gpio13 {
				phandle = <0x80>;

				pin-pwm {
					pins = "gpio13";
					bias-disable;
					function = "alt0";
				};
			};

			spi4_pins {
				brcm,pins = <0x05 0x06 0x07>;
				phandle = <0xa4>;
				brcm,function = <0x07>;
			};

			uart1_gpio32 {
				brcm,pins = <0x20 0x21>;
				phandle = <0x68>;
				brcm,function = <0x02>;
			};

			pwm1_0_gpio40 {
				phandle = <0x1b>;

				pin-pwm {
					pins = "gpio40";
					bias-disable;
					function = "alt0";
				};
			};

			i2c5 {
				brcm,pins = <0x0c 0x0d>;
				phandle = <0xad>;
				brcm,pull = <0x02>;
				brcm,function = <0x02>;
			};

			dpi_16bit_gpio0 {
				brcm,pins = <0x00 0x01 0x02 0x03 0x04 0x05 0x06 0x07 0x08 0x09 0x0a 0x0b 0x0c 0x0d 0x0e 0x0f 0x10 0x11 0x12 0x13>;
				phandle = <0x9e>;
				brcm,function = <0x06>;
			};

			gpclk1_gpio42 {
				brcm,pins = <0x2a>;
				phandle = <0x51>;
				brcm,function = <0x04>;
			};

			i2c6_gpio22 {
				phandle = <0x78>;

				pin-scl {
					pins = "gpio23";
					bias-disable;
					function = "alt5";
				};

				pin-sda {
					pins = "gpio22";
					function = "alt5";
					bias-pull-up;
				};
			};

			uart4_gpio8 {
				phandle = <0x94>;

				pin-tx {
					pins = "gpio8";
					bias-disable;
					function = "alt4";
				};

				pin-rx {
					pins = "gpio9";
					function = "alt4";
					bias-pull-up;
				};
			};

			uart1_gpio40 {
				brcm,pins = <0x28 0x29>;
				phandle = <0x6a>;
				brcm,function = <0x02>;
			};

			emmc_gpio22 {
				brcm,pins = <0x16 0x17 0x18 0x19 0x1a 0x1b>;
				phandle = <0x4d>;
				brcm,function = <0x07>;
			};

			mii_gpio28 {
				phandle = <0x7b>;

				pins-mii {
					pins = "gpio28\0gpio29\0gpio30\0gpio31";
					function = "alt4";
				};
			};

			dpi_16bit_cpadhi_gpio0 {
				brcm,pins = <0x00 0x01 0x02 0x03 0x04 0x05 0x06 0x07 0x08 0x0c 0x0d 0x0e 0x0f 0x10 0x11 0x14 0x15 0x16 0x17 0x18>;
				phandle = <0xa0>;
				brcm,function = <0x06>;
			};

			uart5_pins {
				brcm,pins = <0x0c 0x0d>;
				phandle = <0xb2>;
				brcm,pull = <0x00 0x02>;
				brcm,function = <0x03>;
			};

			spi4_cs_pins {
				brcm,pins = <0x04 0x19>;
				phandle = <0xa5>;
				brcm,function = <0x01>;
			};

			i2c_slave_gpio8 {
				phandle = <0x79>;

				pins-i2c-slave {
					pins = "gpio8\0gpio9\0gpio10\0gpio11";
					function = "alt3";
				};
			};

			gpclk1_gpio50 {
				phandle = <0x6d>;

				pin-gpclk {
					pins = "gpio50";
					bias-disable;
					function = "alt1";
				};
			};
		};

		mmc@7e300000 {
			compatible = "brcm,bcm2835-mmc\0brcm,bcm2835-sdhci";
			clocks = <0x08 0x1c>;
			status = "disabled";
			interrupts = <0x00 0x7e 0x04>;
			brcm,overclock-50 = <0x00>;
			bus-width = <0x04>;
			dma-names = "rx-tx";
			phandle = <0x3b>;
			reg = <0x7e300000 0x100>;
			pinctrl-0 = <0x16>;
			dmas = <0x0c 0x0b>;
			pinctrl-names = "default";
		};

		pixelvalve@7ec12000 {
			compatible = "brcm,bcm2711-pixelvalve3";
			status = "okay";
			interrupts = <0x00 0x6a 0x04>;
			phandle = <0xd1>;
			reg = <0x7ec12000 0x100>;
		};

		spi@7e204000 {
			compatible = "brcm,bcm2835-spi";
			clocks = <0x08 0x14>;
			status = "disabled";
			#address-cells = <0x01>;
			interrupts = <0x00 0x76 0x04>;
			cs-gpios = <0x07 0x08 0x01 0x07 0x07 0x01>;
			#size-cells = <0x00>;
			dma-names = "tx\0rx";
			phandle = <0x34>;
			reg = <0x7e204000 0x200>;
			pinctrl-0 = <0x0e 0x0f>;
			dmas = <0x0c 0x06 0x0c 0x07>;
			pinctrl-names = "default";

			spidev@1 {
				compatible = "spidev";
				#address-cells = <0x01>;
				#size-cells = <0x00>;
				phandle = <0xb4>;
				reg = <0x01>;
				spi-max-frequency = <0x7735940>;
			};

			spidev@0 {
				compatible = "spidev";
				#address-cells = <0x01>;
				#size-cells = <0x00>;
				phandle = <0xb3>;
				reg = <0x00>;
				spi-max-frequency = <0x7735940>;
			};
		};

		serial@7e201600 {
			compatible = "arm,pl011\0arm,primecell";
			clocks = <0x08 0x13 0x08 0x14>;
			clock-names = "uartclk\0apb_pclk";
			status = "disabled";
			interrupts = <0x00 0x79 0x04>;
			phandle = <0xc1>;
			arm,primecell-periphid = <0x241011>;
			reg = <0x7e201600 0x200>;
		};

		i2c@7e804000 {
			compatible = "brcm,bcm2711-i2c\0brcm,bcm2835-i2c";
			clocks = <0x08 0x14>;
			status = "disabled";
			#address-cells = <0x01>;
			interrupts = <0x00 0x75 0x04>;
			#size-cells = <0x00>;
			phandle = <0x36>;
			reg = <0x7e804000 0x1000>;
			clock-frequency = <0x186a0>;
			pinctrl-0 = <0x18>;
			pinctrl-names = "default";
		};

		interrupt-controller@7ef00100 {
			compatible = "brcm,bcm2711-l2-intc\0brcm,l2-intc";
			status = "okay";
			#interrupt-cells = <0x01>;
			interrupts = <0x00 0x60 0x01>;
			phandle = <0x20>;
			reg = <0x7ef00100 0x30>;
			interrupt-controller;
		};

		pwm@7e20c800 {
			compatible = "brcm,bcm2835-pwm";
			clocks = <0x08 0x1e>;
			status = "disabled";
			assigned-clock-rates = <0x989680>;
			assigned-clocks = <0x08 0x1e>;
			phandle = <0xcf>;
			reg = <0x7e20c800 0x28>;
			pinctrl-0 = <0x1b 0x1c>;
			#pwm-cells = <0x02>;
			pinctrl-names = "default";
		};

		clock@7ef00000 {
			compatible = "brcm,brcm2711-dvp";
			clocks = <0x1d>;
			#reset-cells = <0x01>;
			status = "okay";
			#clock-cells = <0x01>;
			phandle = <0x1e>;
			reg = <0x7ef00000 0x10>;
		};

		timer@7e003000 {
			compatible = "brcm,bcm2835-system-timer";
			status = "disabled";
			interrupts = <0x00 0x40 0x04 0x00 0x41 0x04 0x00 0x42 0x04 0x00 0x43 0x04>;
			phandle = <0x4a>;
			reg = <0x7e003000 0x1000>;
			clock-frequency = <0xf4240>;
		};

		i2s@7e203000 {
			compatible = "brcm,bcm2835-i2s";
			clocks = <0x08 0x1f>;
			#sound-dai-cells = <0x00>;
			status = "disabled";
			dma-names = "tx\0rx";
			phandle = <0x33>;
			reg = <0x7e203000 0x24>;
			pinctrl-0 = <0x0d>;
			dmas = <0x0c 0x02 0x0c 0x03>;
			pinctrl-names = "default";
		};

		i2c@7e205a00 {
			compatible = "brcm,bcm2711-i2c\0brcm,bcm2835-i2c";
			clocks = <0x08 0x14>;
			status = "disabled";
			#address-cells = <0x01>;
			interrupts = <0x00 0x75 0x04>;
			#size-cells = <0x00>;
			phandle = <0xca>;
			reg = <0x7e205a00 0x200>;
		};

		hdmi@7ef05700 {
			compatible = "brcm,bcm2711-hdmi1";
			clocks = <0x17 0x0d 0x17 0x0e 0x1e 0x01 0x1f>;
			resets = <0x1e 0x01>;
			reg-names = "hdmi\0dvp\0phy\0rm\0packet\0metadata\0csc\0cec\0hd\0intr2";
			clock-names = "hdmi\0bvb\0audio\0cec";
			ddc = <0x22>;
			status = "okay";
			interrupt-parent = <0x20>;
			interrupts = <0x08 0x07 0x06 0x09 0x0a 0x0b>;
			dma-names = "audio-rx";
			phandle = <0x3f>;
			reg = <0x7ef05700 0x300 0x7ef05300 0x200 0x7ef05f00 0x80 0x7ef05f80 0x80 0x7ef06b00 0x200 0x7ef06f00 0x400 0x7ef00280 0x80 0x7ef09300 0x100 0x7ef20000 0x100 0x7ef00100 0x30>;
			dmas = <0x0c 0x9fa0011>;
			wifi-2.4ghz-coexistence;
			interrupt-names = "cec-tx\0cec-rx\0cec-low\0wakeup\0hpd-connected\0hpd-removed";
		};

		mailbox@7e00b880 {
			compatible = "brcm,bcm2835-mbox";
			#mbox-cells = <0x00>;
			interrupts = <0x00 0x21 0x04>;
			phandle = <0x23>;
			reg = <0x7e00b880 0x40>;
		};

		gpiomem {
			compatible = "brcm,bcm2835-gpiomem";
			reg = <0x7e200000 0x1000>;
		};

		i2c@7ef04500 {
			compatible = "brcm,bcm2711-hdmi-i2c";
			reg-names = "bsc\0auto-i2c";
			status = "okay";
			phandle = <0x21>;
			reg = <0x7ef04500 0x100 0x7ef00b00 0x300>;
			clock-frequency = <0x17cdc>;
		};

		i2c@7e205800 {
			compatible = "brcm,bcm2711-i2c\0brcm,bcm2835-i2c";
			clocks = <0x08 0x14>;
			status = "disabled";
			#address-cells = <0x01>;
			interrupts = <0x00 0x75 0x04>;
			#size-cells = <0x00>;
			phandle = <0xc9>;
			reg = <0x7e205800 0x200>;
		};

		spi@7e204600 {
			compatible = "brcm,bcm2835-spi";
			clocks = <0x08 0x14>;
			status = "disabled";
			#address-cells = <0x01>;
			interrupts = <0x00 0x76 0x04>;
			#size-cells = <0x00>;
			phandle = <0xc4>;
			reg = <0x7e204600 0x200>;
		};

		power {
			compatible = "raspberrypi,bcm2835-power";
			firmware = <0x06>;
			phandle = <0x13>;
			#power-domain-cells = <0x01>;
		};

		pixelvalve@7e206000 {
			compatible = "brcm,bcm2711-pixelvalve0";
			status = "okay";
			interrupts = <0x00 0x6d 0x04>;
			phandle = <0xcc>;
			reg = <0x7e206000 0x100>;
		};

		csi@7e800000 {
			power-domains = <0x13 0x0c>;
			compatible = "brcm,bcm2835-unicam";
			clocks = <0x08 0x2d 0x17 0x04>;
			clock-names = "lp\0vpu";
			status = "disabled";
			#address-cells = <0x01>;
			interrupts = <0x00 0x66 0x04>;
			#size-cells = <0x00>;
			#clock-cells = <0x01>;
			phandle = <0xd7>;
			reg = <0x7e800000 0x800 0x7e802000 0x04>;
		};

		mailbox@7e00b840 {
			compatible = "brcm,bcm2711-vchiq";
			interrupts = <0x00 0x22 0x04>;
			phandle = <0xd4>;
			reg = <0x7e00b840 0x3c>;

			bcm2835_audio {
				brcm,pwm-channels = <0x08>;
				compatible = "brcm,bcm2835-audio";
				brcm,disable-hdmi;
				status = "okay";
				brcm,firmware = <0x06>;
				phandle = <0x37>;
				pinctrl-0 = <0x24>;
				pinctrl-names = "default";
			};
		};

		firmware {
			compatible = "raspberrypi,bcm2835-firmware\0simple-mfd";
			#address-cells = <0x01>;
			mboxes = <0x23>;
			#size-cells = <0x01>;
			phandle = <0x06>;
			dma-ranges;

			clocks {
				compatible = "raspberrypi,firmware-clocks";
				#clock-cells = <0x01>;
				phandle = <0x17>;
			};

			gpio {
				compatible = "raspberrypi,firmware-gpio";
				gpio-line-names = "BT_ON\0WL_ON\0PWR_LED_OFF\0GLOBAL_RESET\0VDD_SD_IO_SEL\0CAM_GPIO\0SD_PWR_ON\0SD_OC_N";
				gpio-controller;
				status = "okay";
				phandle = <0x0b>;
				#gpio-cells = <0x02>;
			};

			reset {
				compatible = "raspberrypi,firmware-reset";
				#reset-cells = <0x01>;
				phandle = <0x2e>;
			};

			vcio {
				compatible = "raspberrypi,vcio";
				phandle = <0xd3>;
			};
		};

		dsi@7e209000 {
			power-domains = <0x13 0x11>;
			compatible = "brcm,bcm2835-dsi0";
			clocks = <0x08 0x20 0x08 0x2f 0x08 0x31>;
			clock-names = "phy\0escape\0pixel";
			status = "disabled";
			#address-cells = <0x01>;
			interrupts = <0x00 0x64 0x04>;
			#size-cells = <0x00>;
			#clock-cells = <0x01>;
			phandle = <0x04>;
			reg = <0x7e209000 0x78>;
			clock-output-names = "dsi0_byte\0dsi0_ddr2\0dsi0_ddr";
		};

		mmcnr@7e300000 {
			compatible = "brcm,bcm2835-mmc\0brcm,bcm2835-sdhci";
			clocks = <0x08 0x1c>;
			status = "okay";
			interrupts = <0x00 0x7e 0x04>;
			brcm,overclock-50 = <0x00>;
			bus-width = <0x04>;
			dma-names = "rx-tx";
			phandle = <0x3c>;
			reg = <0x7e300000 0x100>;
			pinctrl-0 = <0x25>;
			dmas = <0x0c 0x0b>;
			non-removable;
			pinctrl-names = "default";
		};

		fb {
			compatible = "brcm,bcm2708-fb";
			firmware = <0x06>;
			status = "disabled";
			phandle = <0xd9>;
		};

		serial@7e201a00 {
			compatible = "arm,pl011\0arm,primecell";
			clocks = <0x08 0x13 0x08 0x14>;
			clock-names = "uartclk\0apb_pclk";
			status = "disabled";
			interrupts = <0x00 0x79 0x04>;
			phandle = <0xc3>;
			arm,primecell-periphid = <0x241011>;
			reg = <0x7e201a00 0x200>;
		};

		serial@7e201800 {
			compatible = "arm,pl011\0arm,primecell";
			clocks = <0x08 0x13 0x08 0x14>;
			clock-names = "uartclk\0apb_pclk";
			status = "disabled";
			interrupts = <0x00 0x79 0x04>;
			phandle = <0xc2>;
			arm,primecell-periphid = <0x241011>;
			reg = <0x7e201800 0x200>;
		};

		local_intc@40000000 {
			compatible = "brcm,bcm2836-l1-intc";
			phandle = <0xbe>;
			reg = <0x40000000 0x100>;
		};

		dpi@7e208000 {
			compatible = "brcm,bcm2835-dpi";
			clocks = <0x08 0x14 0x08 0x2c>;
			clock-names = "core\0pixel";
			status = "disabled";
			#address-cells = <0x01>;
			#size-cells = <0x00>;
			phandle = <0xb7>;
			reg = <0x7e208000 0x8c>;
		};

		pixelvalve@7e216000 {
			compatible = "brcm,bcm2711-pixelvalve4";
			status = "okay";
			interrupts = <0x00 0x6e 0x04>;
			phandle = <0xd0>;
			reg = <0x7e216000 0x100>;
		};

		i2c@7ef09500 {
			compatible = "brcm,bcm2711-hdmi-i2c";
			reg-names = "bsc\0auto-i2c";
			status = "okay";
			phandle = <0x22>;
			reg = <0x7ef09500 0x100 0x7ef05b00 0x300>;
			clock-frequency = <0x17cdc>;
		};

		mmc@7e202000 {
			compatible = "brcm,bcm2835-sdhost";
			clocks = <0x08 0x14>;
			brcm,pio-limit = <0x01>;
			firmware = <0x06>;
			status = "disabled";
			interrupts = <0x00 0x78 0x04>;
			brcm,overclock-50 = <0x00>;
			bus-width = <0x04>;
			dma-names = "rx-tx";
			phandle = <0x3a>;
			reg = <0x7e202000 0x100>;
			dmas = <0x0c 0x2000000d>;
		};

		i2c0mux {
			compatible = "i2c-mux-pinctrl";
			pinctrl-1 = <0x12>;
			status = "disabled";
			#address-cells = <0x01>;
			i2c-parent = <0x10>;
			#size-cells = <0x00>;
			phandle = <0x35>;
			pinctrl-0 = <0x11>;
			pinctrl-names = "i2c0\0i2c_csi_dsi";

			i2c@0 {
				#address-cells = <0x01>;
				#size-cells = <0x00>;
				phandle = <0xb5>;
				reg = <0x00>;
			};

			i2c@1 {
				#address-cells = <0x01>;
				#size-cells = <0x00>;
				phandle = <0xb6>;
				reg = <0x01>;
			};
		};

		i2c@7e205c00 {
			compatible = "brcm,bcm2711-i2c\0brcm,bcm2835-i2c";
			clocks = <0x08 0x14>;
			status = "disabled";
			#address-cells = <0x01>;
			interrupts = <0x00 0x75 0x04>;
			#size-cells = <0x00>;
			phandle = <0xcb>;
			reg = <0x7e205c00 0x200>;
		};

		vec@7ec13000 {
			power-domains = <0x13 0x07>;
			compatible = "brcm,bcm2711-vec";
			clocks = <0x17 0x0f>;
			status = "disabled";
			interrupts = <0x00 0x7b 0x04>;
			phandle = <0xd2>;
			reg = <0x7ec13000 0x1000>;
		};

		spi@7e204a00 {
			compatible = "brcm,bcm2835-spi";
			clocks = <0x08 0x14>;
			status = "disabled";
			#address-cells = <0x01>;
			interrupts = <0x00 0x76 0x04>;
			#size-cells = <0x00>;
			phandle = <0xc6>;
			reg = <0x7e204a00 0x200>;
		};

		pwm@7e20c000 {
			compatible = "brcm,bcm2835-pwm";
			clocks = <0x08 0x1e>;
			status = "disabled";
			assigned-clock-rates = <0x989680>;
			assigned-clocks = <0x08 0x1e>;
			phandle = <0xbb>;
			reg = <0x7e20c000 0x28>;
			#pwm-cells = <0x02>;
		};

		watchdog@7e100000 {
			compatible = "brcm,bcm2835-pm\0brcm,bcm2835-pm-wdt";
			clocks = <0x08 0x15 0x08 0x1d 0x08 0x17 0x08 0x16>;
			#reset-cells = <0x01>;
			clock-names = "v3d\0peri_image\0h264\0isp";
			system-power-controller;
			phandle = <0x38>;
			reg = <0x7e100000 0x114 0x7e00a000 0x24 0x7ec11000 0x20>;
			#power-domain-cells = <0x01>;
		};

		aux@7e215000 {
			compatible = "brcm,bcm2835-aux";
			clocks = <0x08 0x14>;
			#clock-cells = <0x01>;
			phandle = <0x14>;
			reg = <0x7e215000 0x08>;
		};

		dsi@7e700000 {
			power-domains = <0x13 0x12>;
			compatible = "brcm,bcm2711-dsi1";
			clocks = <0x08 0x23 0x08 0x30 0x08 0x32>;
			clock-names = "phy\0escape\0pixel";
			status = "disabled";
			#address-cells = <0x01>;
			interrupts = <0x00 0x6c 0x04>;
			#size-cells = <0x00>;
			#clock-cells = <0x01>;
			phandle = <0x05>;
			reg = <0x7e700000 0x8c>;
			clock-output-names = "dsi1_byte\0dsi1_ddr2\0dsi1_ddr";
		};

		axiperf {
			compatible = "brcm,bcm2835-axiperf";
			firmware = <0x06>;
			status = "disabled";
			phandle = <0x3d>;
			reg = <0x7e009800 0x100 0x7ee08000 0x100>;
		};

		spi@7e204800 {
			compatible = "brcm,bcm2835-spi";
			clocks = <0x08 0x14>;
			status = "disabled";
			#address-cells = <0x01>;
			interrupts = <0x00 0x76 0x04>;
			#size-cells = <0x00>;
			phandle = <0xc5>;
			reg = <0x7e204800 0x200>;
		};

		sound {
			status = "disabled";
			phandle = <0xda>;
		};

		i2c@7e205000 {
			compatible = "brcm,bcm2711-i2c\0brcm,bcm2835-i2c";
			clocks = <0x08 0x14>;
			status = "disabled";
			#address-cells = <0x01>;
			interrupts = <0x00 0x75 0x04>;
			#size-cells = <0x00>;
			phandle = <0x10>;
			reg = <0x7e205000 0x200>;
			clock-frequency = <0x186a0>;
		};

		txp@7e004000 {
			compatible = "brcm,bcm2835-txp";
			status = "okay";
			interrupts = <0x00 0x4b 0x04>;
			phandle = <0x4b>;
			reg = <0x7e004000 0x20>;
		};

		serial@7e201400 {
			compatible = "arm,pl011\0arm,primecell";
			clocks = <0x08 0x13 0x08 0x14>;
			clock-names = "uartclk\0apb_pclk";
			status = "disabled";
			interrupts = <0x00 0x79 0x04>;
			phandle = <0xc0>;
			arm,primecell-periphid = <0x241011>;
			reg = <0x7e201400 0x200>;
		};

		serial@7e215040 {
			compatible = "brcm,bcm2835-aux-uart";
			clocks = <0x14 0x00>;
			status = "okay";
			interrupts = <0x00 0x5d 0x04>;
			skip-init;
			phandle = <0x32>;
			reg = <0x7e215040 0x40>;
			pinctrl-0 = <0x15>;
			pinctrl-names = "default";

			bluetooth {
				compatible = "brcm,bcm43438-bt";
				shutdown-gpios = <0x0b 0x00 0x00>;
				max-speed = <0x70800>;
				status = "disabled";
				phandle = <0xb8>;
			};
		};

		dma@7e007000 {
			#dma-cells = <0x01>;
			compatible = "brcm,bcm2835-dma";
			brcm,dma-channel-mask = <0x7f5>;
			interrupts = <0x00 0x50 0x04 0x00 0x51 0x04 0x00 0x52 0x04 0x00 0x53 0x04 0x00 0x54 0x04 0x00 0x55 0x04 0x00 0x56 0x04 0x00 0x57 0x04 0x00 0x57 0x04 0x00 0x58 0x04 0x00 0x58 0x04>;
			phandle = <0x0c>;
			reg = <0x7e007000 0xb00>;
			interrupt-names = "dma0\0dma1\0dma2\0dma3\0dma4\0dma5\0dma6\0dma7\0dma8\0dma9\0dma10";
		};

		interrupt-controller@40041000 {
			compatible = "arm,gic-400";
			#interrupt-cells = <0x03>;
			interrupts = <0x01 0x09 0xf04>;
			phandle = <0x01>;
			reg = <0x40041000 0x1000 0x40042000 0x2000 0x40044000 0x2000 0x40046000 0x2000>;
			interrupt-controller;
		};

		spi@7e215080 {
			compatible = "brcm,bcm2835-aux-spi";
			clocks = <0x14 0x01>;
			status = "disabled";
			#address-cells = <0x01>;
			interrupts = <0x00 0x5d 0x04>;
			#size-cells = <0x00>;
			phandle = <0xb9>;
			reg = <0x7e215080 0x40>;
		};

		firmwarekms@7e600000 {
			compatible = "raspberrypi,rpi-firmware-kms-2711";
			status = "disabled";
			interrupts = <0x00 0x70 0x04>;
			brcm,firmware = <0x06>;
			phandle = <0xd5>;
			reg = <0x7e600000 0x100>;
		};

		rng@7e104000 {
			compatible = "brcm,bcm2711-rng200";
			status = "okay";
			phandle = <0x39>;
			reg = <0x7e104000 0x28>;
		};

		pixelvalve@7e20a000 {
			compatible = "brcm,bcm2711-pixelvalve2";
			status = "okay";
			interrupts = <0x00 0x65 0x04>;
			phandle = <0xce>;
			reg = <0x7e20a000 0x100>;
		};

		i2c@7e205600 {
			compatible = "brcm,bcm2711-i2c\0brcm,bcm2835-i2c";
			clocks = <0x08 0x14>;
			status = "disabled";
			#address-cells = <0x01>;
			interrupts = <0x00 0x75 0x04>;
			#size-cells = <0x00>;
			phandle = <0xc8>;
			reg = <0x7e205600 0x200>;
		};

		usb@7e980000 {
			power-domains = <0x13 0x06>;
			compatible = "brcm,bcm2708-usb";
			clocks = <0x19>;
			clock-names = "otg";
			phy-names = "usb2-phy";
			status = "disabled";
			#address-cells = <0x01>;
			interrupts = <0x00 0x49 0x04 0x00 0x28 0x04>;
			#size-cells = <0x00>;
			phandle = <0xbd>;
			phys = <0x1a>;
			reg = <0x7e980000 0x10000 0x7e00b200 0x200>;
			interrupt-names = "usb\0soft";
		};

		smi@7e600000 {
			compatible = "brcm,bcm2835-smi";
			clocks = <0x08 0x2a>;
			status = "disabled";
			interrupts = <0x00 0x70 0x04>;
			assigned-clock-rates = <0x7735940>;
			dma-names = "rx-tx";
			assigned-clocks = <0x08 0x2a>;
			phandle = <0xd6>;
			reg = <0x7e600000 0x100>;
			dmas = <0x0c 0x04>;
		};

		hdmi@7ef00700 {
			compatible = "brcm,bcm2711-hdmi0";
			clocks = <0x17 0x0d 0x17 0x0e 0x1e 0x00 0x1f>;
			resets = <0x1e 0x00>;
			reg-names = "hdmi\0dvp\0phy\0rm\0packet\0metadata\0csc\0cec\0hd\0intr2";
			clock-names = "hdmi\0bvb\0audio\0cec";
			ddc = <0x21>;
			status = "okay";
			interrupt-parent = <0x20>;
			interrupts = <0x00 0x01 0x02 0x03 0x04 0x05>;
			dma-names = "audio-rx";
			phandle = <0x3e>;
			reg = <0x7ef00700 0x300 0x7ef00300 0x200 0x7ef00f00 0x80 0x7ef00f80 0x80 0x7ef01b00 0x200 0x7ef01f00 0x400 0x7ef00200 0x80 0x7ef04300 0x100 0x7ef20000 0x100 0x7ef00100 0x30>;
			dmas = <0x0c 0x9fa000a>;
			wifi-2.4ghz-coexistence;
			interrupt-names = "cec-tx\0cec-rx\0cec-low\0wakeup\0hpd-connected\0hpd-removed";
		};

		spi@7e2150c0 {
			compatible = "brcm,bcm2835-aux-spi";
			clocks = <0x14 0x02>;
			status = "disabled";
			#address-cells = <0x01>;
			interrupts = <0x00 0x5d 0x04>;
			#size-cells = <0x00>;
			phandle = <0xba>;
			reg = <0x7e2150c0 0x40>;
		};

		avs-monitor@7d5d2000 {
			compatible = "brcm,bcm2711-avs-monitor\0syscon\0simple-mfd";
			phandle = <0xbf>;
			reg = <0x7d5d2000 0xf00>;

			thermal {
				compatible = "brcm,bcm2711-thermal";
				#thermal-sensor-cells = <0x00>;
				phandle = <0x02>;
			};
		};
	};

	leds {
		compatible = "gpio-leds";
		phandle = <0xe2>;

		led-act {
			gpios = <0x07 0x2a 0x00>;
			label = "led0";
			phandle = <0x41>;
			default-state = "keep";
			linux,default-trigger = "mmc0";
		};

		led-pwr {
			gpios = <0x0b 0x02 0x01>;
			label = "led1";
			phandle = <0x42>;
			default-state = "keep";
			linux,default-trigger = "default-on";
		};
	};

	cam_dummy_reg {
		compatible = "regulator-fixed";
		status = "okay";
		phandle = <0xe7>;
		regulator-name = "cam-dummy-reg";
	};

	aliases {
		i2c3 = "/soc/i2c@7e205600";
		i2c20 = "/soc/i2c@7ef04500";
		i2c10 = "/soc/i2c0mux/i2c@1";
		spi2 = "/soc/spi@7e2150c0";
		i2c1 = "/soc/i2c@7e804000";
		i2c_vc = "/soc/i2c0mux/i2c@0";
		spi0 = "/soc/spi@7e204000";
		thermal = "/soc/avs-monitor@7d5d2000/thermal";
		sdhost = "/soc/mmc@7e202000";
		aux = "/soc/aux@7e215000";
		gpio = "/soc/gpio@7e200000";
		mmc1 = "/soc/mmcnr@7e300000";
		blconfig = "/reserved-memory/nvram@0";
		blpubkey = "/reserved-memory/nvram@1";
		audio = "/soc/mailbox@7e00b840/bcm2835_audio";
		dma = "/soc/dma@7e007000";
		ethernet0 = "/scb/ethernet@7d580000";
		soc = "/soc";
		i2c6 = "/soc/i2c@7e205c00";
		leds = "/leds";
		spi5 = "/soc/spi@7e204a00";
		mmc = "/soc/mmc@7e300000";
		serial1 = "/soc/serial@7e201000";
		pcie0 = "/scb/pcie@7d500000";
		i2c4 = "/soc/i2c@7e205800";
		i2c21 = "/soc/i2c@7ef09500";
		i2c_arm = "/soc/i2c@7e804000";
		uart0 = "/soc/serial@7e201000";
		spi3 = "/soc/spi@7e204600";
		fb = "/soc/fb";
		i2s = "/soc/i2s@7e203000";
		spi1 = "/soc/spi@7e215080";
		usb = "/soc/usb@7e980000";
		i2c0 = "/soc/i2c0mux/i2c@0";
		mmc2 = "/soc/mmc@7e202000";
		watchdog = "/soc/watchdog@7e100000";
		axiperf = "/soc/axiperf";
		mmc0 = "/emmc2bus/mmc@7e340000";
		sound = "/soc/sound";
		emmc2bus = "/emmc2bus";
		spi6 = "/soc/spi@7e204c00";
		i2c5 = "/soc/i2c@7e205a00";
		mailbox = "/soc/mailbox@7e00b880";
		uart1 = "/soc/serial@7e215040";
		spi4 = "/soc/spi@7e204800";
		random = "/soc/rng@7e104000";
		i2c = "/soc/i2c@7e804000";
		serial0 = "/soc/serial@7e215040";
	};

	chosen {
		bootargs = "coherent_pool=1M 8250.nr_uarts=1 snd_bcm2835.enable_compat_alsa=0 snd_bcm2835.enable_hdmi=1  smsc95xx.macaddr=E4:5F:01:49:32:B5 vc_mem.mem_base=0x3ec00000 vc_mem.mem_size=0x40000000  console=ttyS0,115200 console=tty1 root=PARTUUID=b504a983-02 rootfstype=ext4 fsck.repair=yes rootwait";
		rpi-boardrev-ext = <0x00>;
		log = <0x3ff80000 0x7ffe0>;
		os_prefix;
		overlay_prefix = [6f 76 65 72 6c 61 79 73 2f];
		kaslr-seed = <0x354dec15 0x4d792f63>;

		bootloader {
			version = "c2f8c388c4ee37ad709ace403467d163e8dd91ce";
			capabilities = <0x1f>;
			boot-mode = <0x01>;
			partition = <0x00>;
			rsts = <0x1000>;
			build-timestamp = <0x608adaad>;
			tryboot = <0x00>;
			update-timestamp = <0x608adaad>;
		};
	};

	thermal-zones {

		cpu-thermal {
			thermal-sensors = <0x02>;
			polling-delay = <0x3e8>;
			polling-delay-passive = <0x00>;
			coefficients = <0xfffffe19 0x641b8>;
			phandle = <0x48>;
		};
	};

	cam1_regulator {
		compatible = "regulator-fixed";
		enable-active-high;
		gpio = <0x0b 0x05 0x00>;
		status = "okay";
		phandle = <0xe3>;
		regulator-name = "cam1-reg";
	};

	cam1_clk {
		compatible = "fixed-clock";
		status = "disabled";
		#clock-cells = <0x00>;
		phandle = <0xe4>;
	};

	clk-27M {
		compatible = "fixed-clock";
		#clock-cells = <0x00>;
		phandle = <0x1f>;
		clock-output-names = "27MHz-clock";
		clock-frequency = <0x19bfcc0>;
	};

	timer {
		compatible = "arm,armv8-timer";
		interrupts = <0x01 0x0d 0xf08 0x01 0x0e 0xf08 0x01 0x0b 0xf08 0x01 0x0a 0xf08>;
		arm,cpu-registers-not-fw-configured;
	};

	clk-108M {
		compatible = "fixed-clock";
		#clock-cells = <0x00>;
		phandle = <0x1d>;
		clock-output-names = "108MHz-clock";
		clock-frequency = <0x66ff300>;
	};

	v3dbus {
		compatible = "simple-bus";
		ranges = <0x7c500000 0x00 0xfc500000 0x00 0x3300000 0x40000000 0x00 0xff800000 0x00 0x800000>;
		#address-cells = <0x01>;
		#size-cells = <0x02>;
		phandle = <0xea>;
		dma-ranges = <0x00 0x00 0x00 0x04 0x00>;

		v3d@7ec04000 {
			power-domains = <0x38 0x01>;
			compatible = "brcm,2711-v3d";
			clocks = <0x17 0x05>;
			resets = <0x38 0x00>;
			reg-names = "hub\0core0";
			status = "okay";
			interrupts = <0x00 0x4a 0x04>;
			clocks-names = "v3d";
			phandle = <0xeb>;
			reg = <0x7ec00000 0x00 0x4000 0x7ec04000 0x00 0x4000>;
		};
	};

	phy {
		compatible = "usb-nop-xceiv";
		phandle = <0x1a>;
		#phy-cells = <0x00>;
	};

	emmc2bus {
		compatible = "simple-bus";
		ranges = <0x00 0x7e000000 0x00 0xfe000000 0x1800000>;
		#address-cells = <0x02>;
		#size-cells = <0x01>;
		phandle = <0xdc>;
		dma-ranges = <0x00 0x00 0x00 0x00 0xfc000000>;

		mmc@7e340000 {
			compatible = "brcm,bcm2711-emmc2";
			clocks = <0x08 0x33>;
			broken-cd;
			status = "okay";
			interrupts = <0x00 0x7e 0x04>;
			mmc-ddr-3_3v;
			phandle = <0x40>;
			reg = <0x00 0x7e340000 0x100>;
			vmmc-supply = <0x27>;
			vqmmc-supply = <0x26>;
		};
	};

	fixedregulator_3v3 {
		compatible = "regulator-fixed";
		phandle = <0xe8>;
		regulator-min-microvolt = <0x325aa0>;
		regulator-max-microvolt = <0x325aa0>;
		regulator-always-on;
		regulator-name = "3v3";
	};

	cpus {
		enable-method = "brcm,bcm2836-smp";
		#address-cells = <0x01>;
		#size-cells = <0x00>;
		phandle = <0xdd>;

		cpu@3 {
			compatible = "arm,cortex-a72";
			cpu-release-addr = <0x00 0xf0>;
			device_type = "cpu";
			i-cache-line-size = <0x40>;
			next-level-cache = <0x2c>;
			enable-method = "spin-table";
			phandle = <0x2b>;
			reg = <0x03>;
			d-cache-size = <0x8000>;
			i-cache-size = <0xc000>;
			d-cache-sets = <0x100>;
			i-cache-sets = <0x100>;
			d-cache-line-size = <0x40>;
		};

		cpu@1 {
			compatible = "arm,cortex-a72";
			cpu-release-addr = <0x00 0xe0>;
			device_type = "cpu";
			i-cache-line-size = <0x40>;
			next-level-cache = <0x2c>;
			enable-method = "spin-table";
			phandle = <0x29>;
			reg = <0x01>;
			d-cache-size = <0x8000>;
			i-cache-size = <0xc000>;
			d-cache-sets = <0x100>;
			i-cache-sets = <0x100>;
			d-cache-line-size = <0x40>;
		};

		cpu@2 {
			compatible = "arm,cortex-a72";
			cpu-release-addr = <0x00 0xe8>;
			device_type = "cpu";
			i-cache-line-size = <0x40>;
			next-level-cache = <0x2c>;
			enable-method = "spin-table";
			phandle = <0x2a>;
			reg = <0x02>;
			d-cache-size = <0x8000>;
			i-cache-size = <0xc000>;
			d-cache-sets = <0x100>;
			i-cache-sets = <0x100>;
			d-cache-line-size = <0x40>;
		};

		l2-cache0 {
			compatible = "cache";
			cache-level = <0x02>;
			cache-line-size = <0x40>;
			phandle = <0x2c>;
			cache-size = <0x100000>;
			cache-sets = <0x400>;
		};

		cpu@0 {
			compatible = "arm,cortex-a72";
			cpu-release-addr = <0x00 0xd8>;
			device_type = "cpu";
			i-cache-line-size = <0x40>;
			next-level-cache = <0x2c>;
			enable-method = "spin-table";
			phandle = <0x28>;
			reg = <0x00>;
			d-cache-size = <0x8000>;
			i-cache-size = <0xc000>;
			d-cache-sets = <0x100>;
			i-cache-sets = <0x100>;
			d-cache-line-size = <0x40>;
		};
	};

	sd_io_1v8_reg {
		gpios = <0x0b 0x04 0x00>;
		compatible = "regulator-gpio";
		regulator-settling-time-us = <0x1388>;
		regulator-boot-on;
		status = "okay";
		states = <0x1b7740 0x01 0x325aa0 0x00>;
		phandle = <0x26>;
		regulator-min-microvolt = <0x1b7740>;
		regulator-max-microvolt = <0x325aa0>;
		regulator-always-on;
		regulator-name = "vdd-sd-io";
	};

	fixedregulator_5v0 {
		compatible = "regulator-fixed";
		phandle = <0xe9>;
		regulator-min-microvolt = <0x4c4b40>;
		regulator-max-microvolt = <0x4c4b40>;
		regulator-always-on;
		regulator-name = "5v0";
	};

	axi {

		vc_mem {
			reg = <0x3ec00000 0x40000000 0xc0000000>;
		};
	};
};
